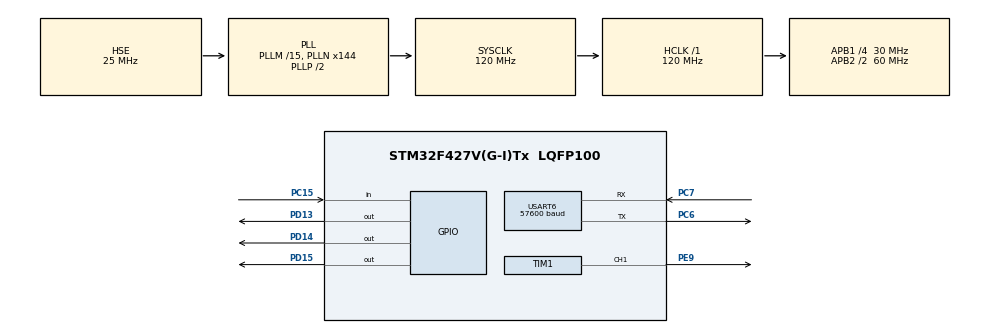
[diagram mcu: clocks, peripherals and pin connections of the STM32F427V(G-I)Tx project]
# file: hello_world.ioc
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Mcu.Family=STM32F4
Mcu.Name=STM32F427V(G-I)Tx
Mcu.Package=LQFP100
NVIC.PriorityGroup=NVIC_PRIORITYGROUP_4
NVIC.USART6_IRQn=true\:0\:0\:false\:false\:true\:true\:true\:true
PA13.Mode=JTAG_5_pins
PA13.Signal=SYS_JTMS-SWDIO
PA14.Mode=JTAG_5_pins
PA14.Signal=SYS_JTCK-SWCLK
PA15.Mode=JTAG_5_pins
PA15.Signal=SYS_JTDI
PB3.Mode=JTAG_5_pins
PB3.Signal=SYS_JTDO-SWO
PB4.Mode=JTAG_5_pins
PB4.Signal=SYS_JTRST
PC15/OSC32_OUT.Signal=GPIO_Input
PC6.Mode=Asynchronous
PC6.Signal=USART6_TX
PC7.Mode=Asynchronous
PC7.Signal=USART6_RX
PD13.Signal=GPIO_Output
PD14.Signal=GPIO_Output
PD15.Signal=GPIO_Output
PE9.Signal=S_TIM1_CH1
PH0/OSC_IN.Mode=HSE-External-Oscillator
PH0/OSC_IN.Signal=RCC_OSC_IN
PH1/OSC_OUT.Mode=HSE-External-Oscillator
PH1/OSC_OUT.Signal=RCC_OSC_OUT
ProjectManager.HeapSize=0x200
ProjectManager.StackSize=0x400
ProjectManager.TargetToolchain=STM32CubeIDE
RCC.48MHZClocksFreq_Value=60000000
RCC.AHBFreq_Value=120000000
RCC.APB1CLKDivider=RCC_HCLK_DIV4
RCC.APB1Freq_Value=30000000
RCC.APB1TimFreq_Value=60000000
RCC.APB2CLKDivider=RCC_HCLK_DIV2
RCC.APB2Freq_Value=60000000
RCC.APB2TimFreq_Value=120000000
RCC.CortexFreq_Value=120000000
RCC.HCLKFreq_Value=120000000
RCC.HSE_VALUE=25000000
RCC.HSI_VALUE=16000000
RCC.LSE_VALUE=32768
RCC.PLLM=15
RCC.PLLN=144
RCC.PLLSourceVirtual=RCC_PLLSOURCE_HSE
RCC.SYSCLKFreq_VALUE=120000000
RCC.SYSCLKSource=RCC_SYSCLKSOURCE_PLLCLK
RCC.VCOOutputFreq_Value=240000000
SH.S_TIM1_CH1.0=TIM1_CH1,PWM Generation1 CH1
TIM1.Channel-PWM\ Generation1\ CH1=TIM_CHANNEL_1
USART6.BaudRate=57600
USART6.VirtualMode=VM_ASYNC
board=custom

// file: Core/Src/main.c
/* USER CODE BEGIN Header */
/**
  ******************************************************************************
  * @file           : main.c
  * @brief          : Main program body
  ******************************************************************************
  * @attention
  *
  * Copyright (c) 2025 STMicroelectronics.
  * All rights reserved.
  *
  * This software is licensed under terms that can be found in the LICENSE file
  * in the root directory of this software component.
  * If no LICENSE file comes with this software, it is provided AS-IS.
  *
  ******************************************************************************
  */
/* USER CODE END Header */
#include <music/notes_handler.h>
#include "main.h"
#include "tim.h"
#include "usart.h"
#include "gpio.h"

/* USER CODE BEGIN Includes */
#include "traffic_light_logic/traffic_light.h"
#include "drivers/uart_driver.h"

/* USER CODE END Includes */

void SystemClock_Config(void);

/* USER CODE BEGIN 0 */
void tone_set_440Hz(void) {
    __HAL_TIM_SET_PRESCALER(&htim1, 119);           // 120 MHz / (119+1) = 1 MHz
    __HAL_TIM_SET_AUTORELOAD(&htim1, 2272);         // 1e6/440 - 1
    __HAL_TIM_SET_COMPARE(&htim1, TIM_CHANNEL_1, 1136); // 50% duty
}

/* USER CODE END 0 */

int main(void)
{

  /* MCU Configuration--------------------------------------------------------*/

  /* Reset of all peripherals, Initializes the Flash interface and the Systick. */
  HAL_Init();

  /* Configure the system clock */
  SystemClock_Config();

  /* Initialize all configured peripherals */
  MX_GPIO_Init();
  MX_USART6_UART_Init();
  MX_TIM1_Init();
  /* USER CODE BEGIN 2 */
  HAL_TIM_PWM_Start(&htim1, TIM_CHANNEL_1);
  uart_set_interrupts(1);

  /* USER CODE END 2 */

  /* Infinite loop */
  /* USER CODE BEGIN WHILE */

  while (1)
  {
	  uart_notes_handler();

    /* USER CODE END WHILE */

  }
}

void SystemClock_Config(void)
{
  RCC_OscInitTypeDef RCC_OscInitStruct = {0};
  RCC_ClkInitTypeDef RCC_ClkInitStruct = {0};

  /** Configure the main internal regulator output voltage
  */
  __HAL_RCC_PWR_CLK_ENABLE();
  __HAL_PWR_VOLTAGESCALING_CONFIG(PWR_REGULATOR_VOLTAGE_SCALE3);

  /** Initializes the RCC Oscillators according to the specified parameters
  * in the RCC_OscInitTypeDef structure.
  */
  RCC_OscInitStruct.OscillatorType = RCC_OSCILLATORTYPE_HSE;
  RCC_OscInitStruct.HSEState = RCC_HSE_ON;
  RCC_OscInitStruct.PLL.PLLState = RCC_PLL_ON;
  RCC_OscInitStruct.PLL.PLLSource = RCC_PLLSOURCE_HSE;
  RCC_OscInitStruct.PLL.PLLM = 15;
  RCC_OscInitStruct.PLL.PLLN = 144;
  RCC_OscInitStruct.PLL.PLLP = RCC_PLLP_DIV2;
  RCC_OscInitStruct.PLL.PLLQ = 4;
  if (HAL_RCC_OscConfig(&RCC_OscInitStruct) != HAL_OK)
  {
    Error_Handler();
  }

  /** Initializes the CPU, AHB and APB buses clocks
  */
  RCC_ClkInitStruct.ClockType = RCC_CLOCKTYPE_HCLK|RCC_CLOCKTYPE_SYSCLK
                              |RCC_CLOCKTYPE_PCLK1|RCC_CLOCKTYPE_PCLK2;
  RCC_ClkInitStruct.SYSCLKSource = RCC_SYSCLKSOURCE_PLLCLK;
  RCC_ClkInitStruct.AHBCLKDivider = RCC_SYSCLK_DIV1;
  RCC_ClkInitStruct.APB1CLKDivider = RCC_HCLK_DIV4;
  RCC_ClkInitStruct.APB2CLKDivider = RCC_HCLK_DIV2;

  if (HAL_RCC_ClockConfig(&RCC_ClkInitStruct, FLASH_LATENCY_3) != HAL_OK)
  {
    Error_Handler();
  }
}

void Error_Handler(void)
{
  __disable_irq();
  while (1)
  {
  }
}
